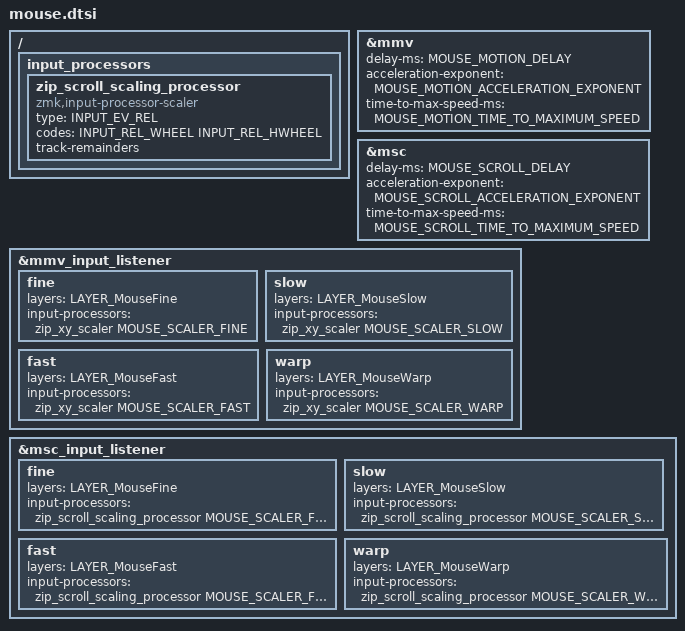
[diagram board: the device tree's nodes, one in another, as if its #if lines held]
#define MSC_UP SCRL_UP
#define MSC_DN SCRL_DOWN
#define MSC_L  SCRL_LEFT
#define MSC_R  SCRL_RIGHT
//
// MOUSE_MOTION_DELAY defines how long to wait (milliseconds) before starting
// to move the mouse pointer.
//
#ifndef MOUSE_MOTION_DELAY
#define MOUSE_MOTION_DELAY 0
#endif

//
// MOUSE_MOTION_ACCELERATION_EXPONENT sets how the mouse pointer accelerates:
//
// acceleration exponent 0: uniform speed
// acceleration exponent 1: uniform acceleration
// acceleration exponent 2: uniform jerk
//
#ifndef MOUSE_MOTION_ACCELERATION_EXPONENT
#define MOUSE_MOTION_ACCELERATION_EXPONENT 1
#endif

//
// MOUSE_MOTION_TIME_TO_MAXIMUM_SPEED defines how long to wait (milliseconds)
// before the mouse pointer speed is suddenly boosted to the maximum value.
//
#ifndef MOUSE_MOTION_TIME_TO_MAXIMUM_SPEED
#define MOUSE_MOTION_TIME_TO_MAXIMUM_SPEED 300
#endif

//
// MOUSE_MOTION_MAXIMUM_SPEED defines how quickly the mouse pointer can move.
//
#ifndef MOUSE_MOTION_MAXIMUM_SPEED
#define MOUSE_MOTION_MAXIMUM_SPEED 600
#endif

//
// MOUSE_SCROLL_DELAY defines how long to wait (milliseconds) before starting
// to move the mouse pointer.
//
#ifndef MOUSE_SCROLL_DELAY
#define MOUSE_SCROLL_DELAY 0
#endif

//
// MOUSE_SCROLL_ACCELERATION_EXPONENT sets how the mouse pointer accelerates:
//
// acceleration exponent 0: uniform speed
// acceleration exponent 1: uniform acceleration
// acceleration exponent 2: uniform jerk
//
#ifndef MOUSE_SCROLL_ACCELERATION_EXPONENT
#define MOUSE_SCROLL_ACCELERATION_EXPONENT 0
#endif

//
// MOUSE_SCROLL_TIME_TO_MAXIMUM_SPEED defines how long to wait (milliseconds)
// before the mouse pointer speed is suddenly boosted to the maximum value.
//
#ifndef MOUSE_SCROLL_TIME_TO_MAXIMUM_SPEED
#define MOUSE_SCROLL_TIME_TO_MAXIMUM_SPEED 300
#endif

//
// MOUSE_SCROLL_MAXIMUM_SPEED defines how quickly the mouse wheel can scroll.
//
#ifndef MOUSE_SCROLL_MAXIMUM_SPEED
#define MOUSE_SCROLL_MAXIMUM_SPEED 10
#endif

//
// MOUSE_SCALER_FINE sets parameters for the &zip_xy_scaler input processor:
// https://zmk.dev/docs/keymaps/input-processors/scaler
//
#ifndef MOUSE_SCALER_FINE
#define MOUSE_SCALER_FINE 1 16
#endif

//
// MOUSE_SCALER_SLOW sets parameters for the &zip_xy_scaler input processor:
// https://zmk.dev/docs/keymaps/input-processors/scaler
//
#ifndef MOUSE_SCALER_SLOW
#define MOUSE_SCALER_SLOW 1 4
#endif

//
// MOUSE_SCALER_FAST sets parameters for the &zip_xy_scaler input processor:
// https://zmk.dev/docs/keymaps/input-processors/scaler
//
#ifndef MOUSE_SCALER_FAST
#define MOUSE_SCALER_FAST 4 1
#endif

//
// MOUSE_SCALER_WARP sets parameters for the &zip_xy_scaler input processor:
// https://zmk.dev/docs/keymaps/input-processors/scaler
//
#ifndef MOUSE_SCALER_WARP
#define MOUSE_SCALER_WARP 12 1
#endif

//  ==== MOUSE-KEY <section begins> ====
#ifndef ZMK_POINTING_DEFAULT_MOVE_VAL 
#define ZMK_POINTING_DEFAULT_MOVE_VAL MOUSE_MOTION_MAXIMUM_SPEED
#endif
#ifndef ZMK_POINTING_DEFAULT_SCRL_VAL 
#define ZMK_POINTING_DEFAULT_SCRL_VAL MOUSE_SCROLL_MAXIMUM_SPEED
#endif

&mmv {
  delay-ms = <MOUSE_MOTION_DELAY>;
  acceleration-exponent = <MOUSE_MOTION_ACCELERATION_EXPONENT>;
  time-to-max-speed-ms = <MOUSE_MOTION_TIME_TO_MAXIMUM_SPEED>;
};

&msc {
  delay-ms = <MOUSE_SCROLL_DELAY>;
  acceleration-exponent = <MOUSE_SCROLL_ACCELERATION_EXPONENT>;
  time-to-max-speed-ms = <MOUSE_SCROLL_TIME_TO_MAXIMUM_SPEED>;
};

//
// Scaling for mouse movement, based on @caksoylar's example:
// https://github.com/caksoylar/zmk-config/commit/0020c23c544cd7111013f0114609d1fb90e0e475
//
// #include <input/processors.dtsi>
&mmv_input_listener {
  #ifdef LAYER_MouseFine
  fine {
    layers = <LAYER_MouseFine>;
    input-processors = <&zip_xy_scaler MOUSE_SCALER_FINE>;
  };
  #endif
  #ifdef LAYER_MouseSlow
  slow {
    layers = <LAYER_MouseSlow>;
    input-processors = <&zip_xy_scaler MOUSE_SCALER_SLOW>;
  };
  #endif
  #ifdef LAYER_MouseFast
  fast {
    layers = <LAYER_MouseFast>;
    input-processors = <&zip_xy_scaler MOUSE_SCALER_FAST>;
  };
  #endif
  #ifdef LAYER_MouseWarp
  warp {
    layers = <LAYER_MouseWarp>;
    input-processors = <&zip_xy_scaler MOUSE_SCALER_WARP>;
  };
  #endif
};

//
// Scaling for mouse scrolling, based on @caksoylar's example:
// https://github.com/caksoylar/zmk-config/commit/e35ee2f08788927683df7bbdd7fc73434473886e
//
//#include <zephyr/dt-bindings/input/input-event-codes.h>
/ {
  input_processors {
    zip_scroll_scaling_processor: zip_scroll_scaling_processor {
      compatible = "zmk,input-processor-scaler";
      #input-processor-cells = <2>;
      type = <INPUT_EV_REL>;
      codes = <INPUT_REL_WHEEL INPUT_REL_HWHEEL>;
      track-remainders;
    };
  };
};
&msc_input_listener {
  #ifdef LAYER_MouseFine
  fine {
    layers = <LAYER_MouseFine>;
    input-processors = <&zip_scroll_scaling_processor MOUSE_SCALER_FINE>;
  };
  #endif
  #ifdef LAYER_MouseSlow
  slow {
    layers = <LAYER_MouseSlow>;
    input-processors = <&zip_scroll_scaling_processor MOUSE_SCALER_SLOW>;
  };
  #endif
  #ifdef LAYER_MouseFast
  fast {
    layers = <LAYER_MouseFast>;
    input-processors = <&zip_scroll_scaling_processor MOUSE_SCALER_FAST>;
  };
  #endif
  #ifdef LAYER_MouseWarp
  warp {
    layers = <LAYER_MouseWarp>;
    input-processors = <&zip_scroll_scaling_processor MOUSE_SCALER_WARP>;
  };
  #endif
};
